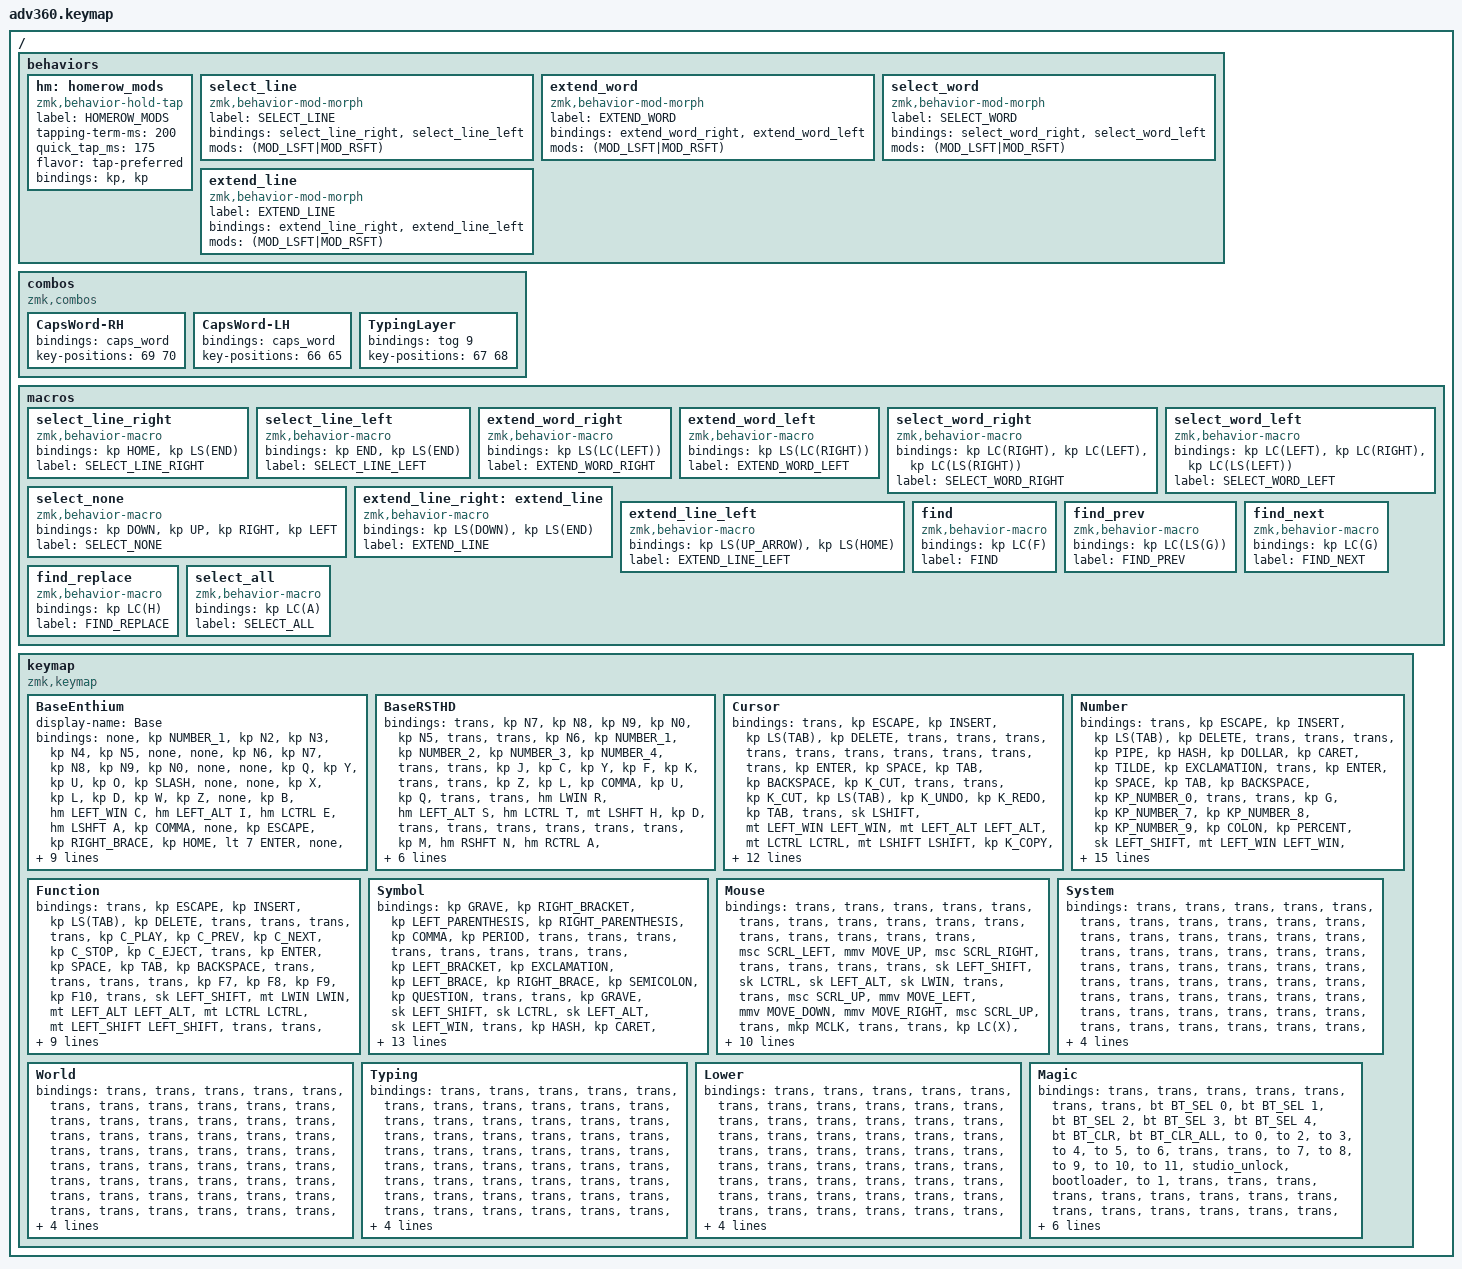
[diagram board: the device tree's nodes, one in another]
#include <dt-bindings/zmk/stp.h>
#include <behaviors.dtsi>
#include <dt-bindings/zmk/bt.h>
#include <dt-bindings/zmk/keys.h>
#include <dt-bindings/zmk/pointing.h>

/ {
    behaviors {
        #include "macros.dtsi"
      #include "version.dtsi"

        hm: homerow_mods {
            compatible = "zmk,behavior-hold-tap";
            label = "HOMEROW_MODS";
            #binding-cells = <2>;
            tapping-term-ms = <200>;
            quick_tap_ms = <175>;
            flavor = "tap-preferred";
            bindings = <&kp>, <&kp>;
        };

        select_line: select_line {
            compatible = "zmk,behavior-mod-morph";
            label = "SELECT_LINE";
            bindings = <&select_line_right>, <&select_line_left>;

            #binding-cells = <0>;
            mods = <(MOD_LSFT|MOD_RSFT)>;
        };

        extend_word: extend_word {
            compatible = "zmk,behavior-mod-morph";
            label = "EXTEND_WORD";
            bindings = <&extend_word_right>, <&extend_word_left>;

            #binding-cells = <0>;
            mods = <(MOD_LSFT|MOD_RSFT)>;
        };

        select_word: select_word {
            compatible = "zmk,behavior-mod-morph";
            label = "SELECT_WORD";
            bindings = <&select_word_right>, <&select_word_left>;

            #binding-cells = <0>;
            mods = <(MOD_LSFT|MOD_RSFT)>;
        };

        extend_line: extend_line {
            compatible = "zmk,behavior-mod-morph";
            label = "EXTEND_LINE";
            bindings = <&extend_line_right>, <&extend_line_left>;

            #binding-cells = <0>;
            mods = <(MOD_LSFT|MOD_RSFT)>;
        };
    };

    combos {
        compatible = "zmk,combos";

        CapsWord-RH {
            bindings = <&caps_word>;
            key-positions = <69 70>;
        };

        CapsWord-LH {
            bindings = <&caps_word>;
            key-positions = <66 65>;
        };

        TypingLayer {
            bindings = <&tog 9>;
            key-positions = <67 68>;
        };
    };

    macros {
        select_line_right: select_line_right {
            compatible = "zmk,behavior-macro";
            #binding-cells = <0>;
            bindings = <&kp HOME &kp LS(END)>;
            label = "SELECT_LINE_RIGHT";
        };

        select_line_left: select_line_left {
            compatible = "zmk,behavior-macro";
            #binding-cells = <0>;
            bindings = <&kp END &kp LS(END)>;
            label = "SELECT_LINE_LEFT";
        };

        extend_word_right: extend_word_right {
            compatible = "zmk,behavior-macro";
            #binding-cells = <0>;
            bindings = <&kp LS(LC(LEFT))>;
            label = "EXTEND_WORD_RIGHT";
        };

        extend_word_left: extend_word_left {
            compatible = "zmk,behavior-macro";
            #binding-cells = <0>;
            bindings = <&kp LS(LC(RIGHT))>;
            label = "EXTEND_WORD_LEFT";
        };

        select_word_right: select_word_right {
            compatible = "zmk,behavior-macro";
            #binding-cells = <0>;
            bindings = <&kp LC(RIGHT) &kp LC(LEFT) &kp LC(LS(RIGHT))>;
            label = "SELECT_WORD_RIGHT";
        };

        select_word_left: select_word_left {
            compatible = "zmk,behavior-macro";
            #binding-cells = <0>;
            bindings = <&kp LC(LEFT) &kp LC(RIGHT) &kp LC(LS(LEFT))>;
            label = "SELECT_WORD_LEFT";
        };

        select_none: select_none {
            compatible = "zmk,behavior-macro";
            #binding-cells = <0>;
            bindings = <&kp DOWN &kp UP &kp RIGHT &kp LEFT>;
            label = "SELECT_NONE";
        };

        extend_line_right: extend_line {
            compatible = "zmk,behavior-macro";
            #binding-cells = <0>;
            bindings = <&kp LS(DOWN) &kp LS(END)>;
            label = "EXTEND_LINE";
        };

        extend_line_left: extend_line_left {
            compatible = "zmk,behavior-macro";
            #binding-cells = <0>;
            bindings = <&kp LS(UP_ARROW) &kp LS(HOME)>;
            label = "EXTEND_LINE_LEFT";
        };

        find: find {
            compatible = "zmk,behavior-macro";
            #binding-cells = <0>;
            bindings = <&kp LC(F)>;
            label = "FIND";
        };

        find_prev: find_prev {
            compatible = "zmk,behavior-macro";
            #binding-cells = <0>;
            bindings = <&kp LC(LS(G))>;
            label = "FIND_PREV";
        };

        find_next: find_next {
            compatible = "zmk,behavior-macro";
            #binding-cells = <0>;
            bindings = <&kp LC(G)>;
            label = "FIND_NEXT";
        };

        find_replace: find_replace {
            compatible = "zmk,behavior-macro";
            #binding-cells = <0>;
            bindings = <&kp LC(H)>;
            label = "FIND_REPLACE";
        };

        select_all: select_all {
            compatible = "zmk,behavior-macro";
            #binding-cells = <0>;
            bindings = <&kp LC(A)>;
            label = "SELECT_ALL";
        };
    };

    keymap {
        compatible = "zmk,keymap";

        BaseEnthium {
            display-name = "Base";
            bindings = <
&none   &kp NUMBER_1    &kp N2          &kp N3          &kp N4           &kp N5         &none                                                                        &none    &kp N6  &kp N7            &kp N8        &kp N9           &kp N0      &none
&none   &kp Q           &kp Y           &kp U           &kp O            &kp SLASH      &none                                                                        &none    &kp X   &kp L             &kp D         &kp W            &kp Z       &none
&kp B   &hm LEFT_WIN C  &hm LEFT_ALT I  &hm LCTRL E     &hm LSHFT A      &kp COMMA      &none        &kp ESCAPE  &kp RIGHT_BRACE      &kp HOME      &lt 7 ENTER      &none    &kp K   &hm RSHFT H       &hm RCTRL T   &hm RIGHT_ALT N  &hm RWIN S  &kp V
&none   &kp SQT         &kp MINUS       &kp EQUAL       &kp PERIOD       &kp SEMICOLON                           &kp LEFT_BRACE       &kp END                                 &kp J   &kp M             &kp G         &kp P            &kp F       &trans
&mo 11  &none           &none           &kp LEFT_ARROW  &kp RIGHT_ARROW                 &lt 2 SPACE  &lt 3 TAB   &lt 9 INS            &lt 9 DELETE  &lt 6 BACKSPACE  &lt 5 R          &lt 8 DOWN_ARROW  &kp UP_ARROW  &none            &none       &mo 11
            >;
        };

        BaseRSTHD {
            bindings = <
&trans  &kp N7      &kp N8          &kp N9       &kp N0       &kp N5  &trans                                      &trans   &kp N6  &kp NUMBER_1  &kp NUMBER_2  &kp NUMBER_3     &kp NUMBER_4  &trans
&trans  &kp J       &kp C           &kp Y        &kp F        &kp K   &trans                                      &trans   &kp Z   &kp L         &kp COMMA     &kp U            &kp Q         &trans
&trans  &hm LWIN R  &hm LEFT_ALT S  &hm LCTRL T  &mt LSHFT H  &kp D   &trans  &trans  &trans      &trans  &trans  &trans   &kp M   &hm RSHFT N   &hm RCTRL A   &hm RIGHT_ALT I  &hm RWIN O    &kp SQT
&trans  &kp SLASH   &kp V           &kp G        &kp P        &kp B                   &trans      &trans                   &kp X   &kp W         &kp PERIOD    &kp SEMICOLON    &kp MINUS     &trans
&trans  &trans      &trans          &trans       &trans               &trans  &trans  &trans      &trans  &trans  &lt 5 E          &trans        &trans        &trans           &trans        &trans
            >;
        };

        Cursor {
            bindings = <
&trans           &kp ESCAPE             &kp INSERT             &kp LS(TAB)      &kp DELETE         &trans       &trans                                                        &trans        &trans       &trans          &trans          &trans         &trans         &trans
&trans           &kp ENTER              &kp SPACE              &kp TAB          &kp BACKSPACE      &kp K_CUT    &trans                                                        &trans        &kp K_CUT    &kp LS(TAB)     &kp K_UNDO      &kp K_REDO     &kp TAB        &trans
&sk LSHIFT       &mt LEFT_WIN LEFT_WIN  &mt LEFT_ALT LEFT_ALT  &mt LCTRL LCTRL  &mt LSHIFT LSHIFT  &kp K_COPY   &trans  &kp LS(TAB)  &kp TAB      &select_none  &extend_word  &trans        &kp K_COPY   &kp LEFT_ARROW  &kp DOWN_ARROW  &kp UP_ARROW   &kp RIGHT      &sk LSHIFT
&trans           &select_all            &select_line           &select_word     &find              &kp K_PASTE                       &trans       &extend_line                              &kp K_PASTE  &kp LC(HOME)    &kp PAGE_UP     &kp PAGE_DOWN  &kp RC(END)    &trans
&kp C_AC_SEARCH  &kp K_UNDO             &kp K_REDO             &find_prev       &find_next                      &trans  &trans       &trans       &kp LC(A)     &select_line  &select_word               &find           &find_prev      &find_next     &find_replace  &kp C_AC_SEARCH
            >;
        };

        Number {
            bindings = <
&trans          &kp ESCAPE             &kp INSERT             &kp LS(TAB)      &kp DELETE                 &trans           &trans                                                    &trans           &kp PIPE  &kp HASH          &kp DOLLAR            &kp CARET              &kp TILDE          &kp EXCLAMATION
&trans          &kp ENTER              &kp SPACE              &kp TAB          &kp BACKSPACE              &kp KP_NUMBER_0  &trans                                                    &trans           &kp G     &kp KP_NUMBER_7   &kp KP_NUMBER_8       &kp KP_NUMBER_9        &kp COLON          &kp PERCENT
&sk LEFT_SHIFT  &mt LEFT_WIN LEFT_WIN  &mt LEFT_ALT LEFT_ALT  &mt LCTRL LCTRL  &mt LEFT_SHIFT LEFT_SHIFT  &kp X            &trans  &trans  &trans      &kp LESS_THAN     &kp COMMA   &trans           &kp K     &kp KP_NUMBER_4   &kp KP_NUMBER_5       &kp KP_NUMBER_6        &kp MINUS          &kp PLUS
&kp E           &select_all            &select_line           &select_word     &find                      &trans                           &trans      &kp GREATER_THAN                               &kp J     &kp KP_NUMBER_1   &kp KP_NUMBER_2       &kp KP_NUMBER_3        &kp SLASH          &kp ASTERISK
&kp UNDERSCORE  &kp K_UNDO             &kp K_REDO             &find_prev       &find_next                                  &trans  &trans  &trans      &kp EQUAL         &kp PERIOD  &kp KP_NUMBER_0            &kp LEFT_BRACKET  &kp LEFT_PARENTHESIS  &kp RIGHT_PARENTHESIS  &kp RIGHT_BRACKET  &kp AT_SIGN
            >;
        };

        Function {
            bindings = <
&trans          &kp ESCAPE     &kp INSERT             &kp LS(TAB)      &kp DELETE                 &trans  &trans                                                           &trans           &trans  &kp C_PLAY  &kp C_PREV  &kp C_NEXT  &kp C_STOP  &kp C_EJECT
&trans          &kp ENTER      &kp SPACE              &kp TAB          &kp BACKSPACE              &trans  &trans                                                           &trans           &trans  &kp F7      &kp F8      &kp F9      &kp F10     &trans
&sk LEFT_SHIFT  &mt LWIN LWIN  &mt LEFT_ALT LEFT_ALT  &mt LCTRL LCTRL  &mt LEFT_SHIFT LEFT_SHIFT  &trans  &trans  &trans  &trans      &kp C_PREV        &kp C_NEXT         &trans           &trans  &kp F4      &kp F5      &kp F6      &kp F11     &trans
&trans          &select_all    &select_line           &select_word     &find                      &trans                  &trans      &kp K_PLAY_PAUSE                                      &trans  &kp F1      &kp F2      &kp F3      &kp F12     &trans
&trans          &kp K_UNDO     &kp K_REDO             &find_prev       &find_next                         &trans  &trans  &trans      &kp K_MUTE        &kp C_VOLUME_DOWN  &kp C_VOLUME_UP          &trans      &trans      &trans      &trans      &trans
            >;
        };

        Symbol {
            bindings = <
&kp GRAVE         &kp RIGHT_BRACKET  &kp LEFT_PARENTHESIS  &kp RIGHT_PARENTHESIS  &kp COMMA         &kp PERIOD    &trans                                                        &trans  &trans             &trans          &trans       &trans        &trans        &trans
&kp LEFT_BRACKET  &kp EXCLAMATION    &kp LEFT_BRACE        &kp RIGHT_BRACE        &kp SEMICOLON     &kp QUESTION  &trans                                                        &trans  &kp GRAVE          &sk LEFT_SHIFT  &sk LCTRL    &sk LEFT_ALT  &sk LEFT_WIN  &trans
&kp HASH          &kp CARET          &kp EQUAL             &kp UNDERSCORE         &kp DOLLAR        &kp ASTERISK  &trans       &kp BACKSLASH  &kp ASTERISK      &trans  &trans  &trans  &kp DOUBLE_QUOTES  &kp BACKSPACE   &kp TAB      &kp SPACE     &kp ENTER     &trans
&kp TILDE         &kp GREATER_THAN   &kp PIPE              &kp MINUS              &kp GREATER_THAN  &kp SLASH                                 &kp PERIOD        &trans                  &kp SQT            &kp DELETE      &kp LS(TAB)  &kp INSERT    &kp ESCAPE    &trans
&trans            &kp AMPERSAND      &kp SQT               &kp DOUBLE_QUOTES      &kp PLUS                        &kp PERCENT  &kp COLON      &kp AT_SIGN       &trans  &trans  &trans                     &trans          &trans       &trans        &trans        &trans
            >;
        };

        Mouse {
            bindings = <
&trans  &trans          &trans          &trans          &trans           &trans          &trans                                                    &trans     &trans          &trans          &trans          &trans           &trans     &trans
&trans  &trans          &msc SCRL_LEFT  &mmv MOVE_UP    &msc SCRL_RIGHT  &trans          &trans                                                    &trans     &trans          &sk LEFT_SHIFT  &sk LCTRL       &sk LEFT_ALT     &sk LWIN   &trans
&trans  &msc SCRL_UP    &mmv MOVE_LEFT  &mmv MOVE_DOWN  &mmv MOVE_RIGHT  &msc SCRL_UP    &trans     &mkp MCLK  &trans        &trans     &kp LC(X)  &trans     &msc SCRL_UP    &trans          &trans          &trans           &mkp LCLK  &mkp MB4
&trans  &msc SCRL_DOWN  &trans          &trans          &trans           &msc SCRL_DOWN                        &mkp MB5      &trans                           &msc SCRL_DOWN  &msc SCRL_LEFT  &mmv MOVE_UP    &msc SCRL_RIGHT  &mkp RCLK  &mkp MB5
&trans  &trans          &trans          &trans          &trans                           &mkp LCLK  &mkp RCLK  &mkp MB4      &kp LC(V)  &trans     &kp LC(C)                  &mmv MOVE_LEFT  &mmv MOVE_DOWN  &mmv MOVE_RIGHT  &mkp MCLK  &trans
            >;
        };

        System {
            bindings = <
&trans  &trans  &trans  &trans  &trans  &trans  &trans                                      &trans  &trans  &trans  &trans  &trans  &trans  &trans
&trans  &trans  &trans  &trans  &trans  &trans  &trans                                      &trans  &trans  &trans  &trans  &trans  &trans  &trans
&trans  &trans  &trans  &trans  &trans  &trans  &trans  &trans  &trans      &trans  &trans  &trans  &trans  &trans  &trans  &trans  &trans  &trans
&trans  &trans  &trans  &trans  &trans  &trans                  &trans      &trans                  &trans  &trans  &trans  &trans  &trans  &trans
&trans  &trans  &trans  &trans  &trans          &trans  &trans  &trans      &trans  &trans  &trans          &trans  &trans  &trans  &trans  &trans
            >;
        };

        World {
            bindings = <
&trans  &trans  &trans  &trans  &trans  &trans  &trans                                      &trans  &trans  &trans  &trans  &trans  &trans  &trans
&trans  &trans  &trans  &trans  &trans  &trans  &trans                                      &trans  &trans  &trans  &trans  &trans  &trans  &trans
&trans  &trans  &trans  &trans  &trans  &trans  &trans  &trans  &trans      &trans  &trans  &trans  &trans  &trans  &trans  &trans  &trans  &trans
&trans  &trans  &trans  &trans  &trans  &trans                  &trans      &trans                  &trans  &trans  &trans  &trans  &trans  &trans
&trans  &trans  &trans  &trans  &trans          &trans  &trans  &trans      &trans  &trans  &trans          &trans  &trans  &trans  &trans  &trans
            >;
        };

        Typing {
            bindings = <
&trans  &trans  &trans  &trans  &trans  &trans  &trans                                      &trans  &trans  &trans  &trans  &trans  &trans  &trans
&trans  &trans  &trans  &trans  &trans  &trans  &trans                                      &trans  &trans  &trans  &trans  &trans  &trans  &trans
&trans  &trans  &trans  &trans  &trans  &trans  &trans  &trans  &trans      &trans  &trans  &trans  &trans  &trans  &trans  &trans  &trans  &trans
&trans  &trans  &trans  &trans  &trans  &trans                  &trans      &trans                  &trans  &trans  &trans  &trans  &trans  &trans
&trans  &trans  &trans  &trans  &trans          &trans  &trans  &trans      &trans  &trans  &trans          &trans  &trans  &trans  &trans  &trans
            >;
        };

        Lower {
            bindings = <
&trans  &trans  &trans  &trans  &trans  &trans  &trans                                      &trans  &trans  &trans  &trans  &trans  &trans  &trans
&trans  &trans  &trans  &trans  &trans  &trans  &trans                                      &trans  &trans  &trans  &trans  &trans  &trans  &trans
&trans  &trans  &trans  &trans  &trans  &trans  &trans  &trans  &trans      &trans  &trans  &trans  &trans  &trans  &trans  &trans  &trans  &trans
&trans  &trans  &trans  &trans  &trans  &trans                  &trans      &trans                  &trans  &trans  &trans  &trans  &trans  &trans
&trans  &trans  &trans  &trans  &trans          &trans  &trans  &trans      &trans  &trans  &trans          &trans  &trans  &trans  &trans  &trans
            >;
        };

        Magic {
            bindings = <
&trans       &trans  &trans  &trans  &trans  &trans  &trans                                      &bt BT_SEL 0  &bt BT_SEL 1  &bt BT_SEL 2  &bt BT_SEL 3  &bt BT_SEL 4  &bt BT_CLR  &bt BT_CLR_ALL
&to 0        &to 2   &to 3   &to 4   &to 5   &to 6   &trans                                      &trans        &to 7         &to 8         &to 9         &to 10        &to 11      &studio_unlock
&bootloader  &to 1   &trans  &trans  &trans  &trans  &trans  &trans  &trans      &trans  &trans  &trans        &trans        &trans        &trans        &trans        &trans      &bootloader
&sys_reset   &trans  &trans  &trans  &trans  &trans                  &trans      &trans                        &trans        &trans        &trans        &trans        &trans      &sys_reset
&trans       &trans  &trans  &trans  &trans          &trans  &trans  &trans      &trans  &trans  &trans                      &trans        &trans        &trans        &trans      &trans
            >;
        };
    };
};
